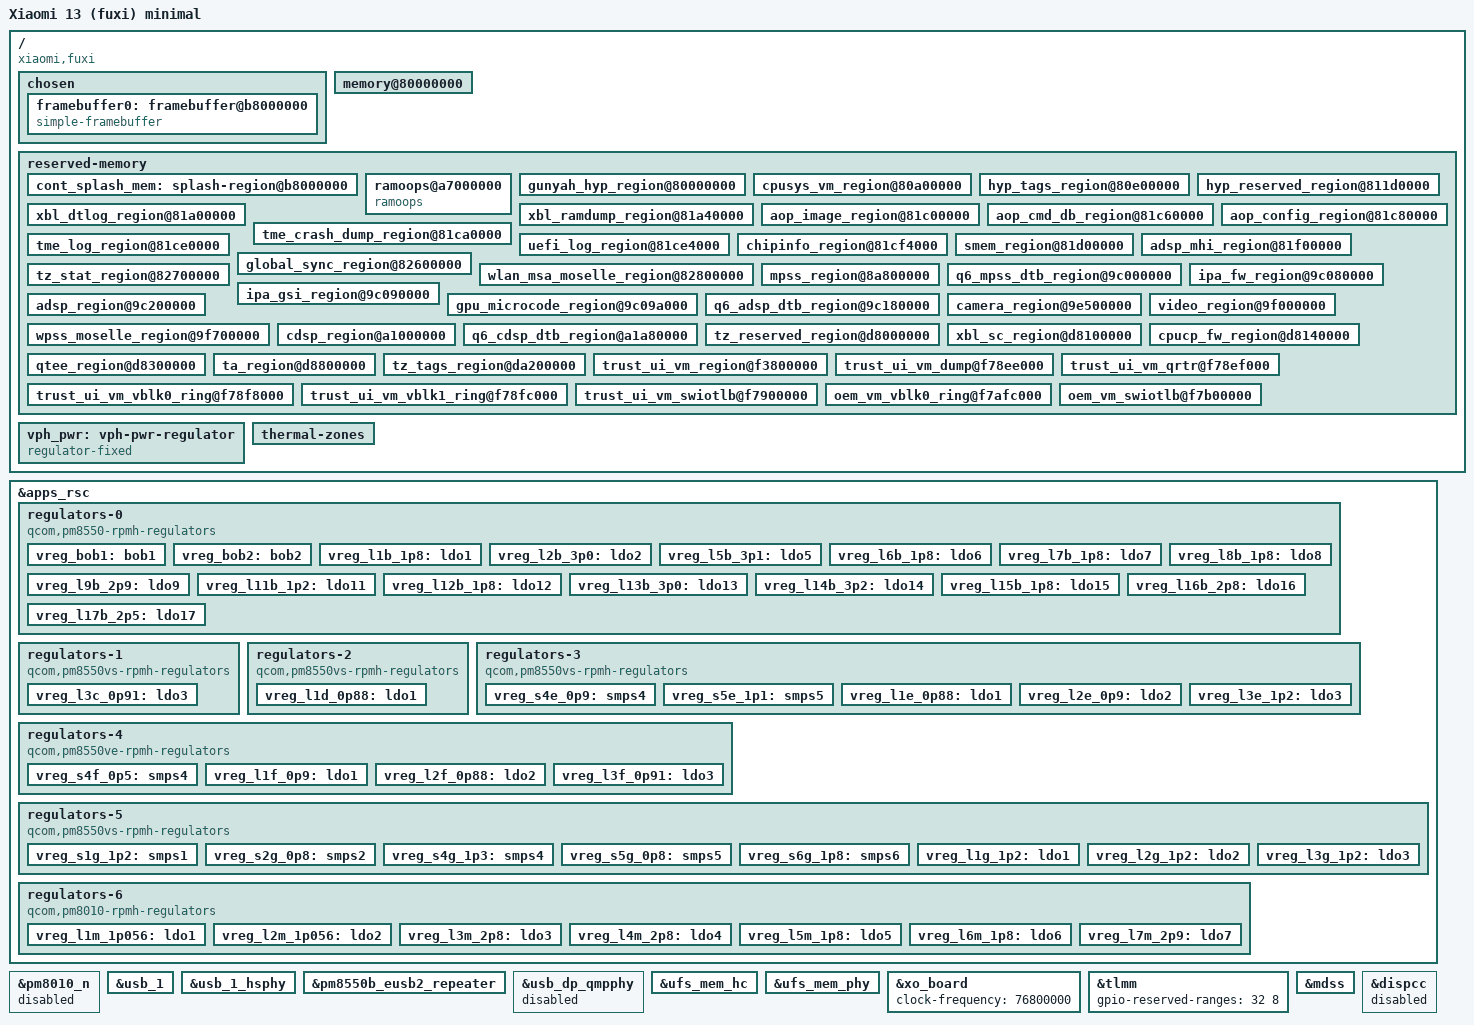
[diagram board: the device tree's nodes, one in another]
// SPDX-License-Identifier: BSD-3-Clause
/*
 * Xiaomi 13 (fuxi) 最小主线板级 DTS —— 只为“内核能启动 + USB 串口工作”
 * 生成方式：从 sm8550-mtp.dts 裁剪（保留 PMIC 调压器与 USB 子树）
 */

/dts-v1/;

#include <dt-bindings/regulator/qcom,rpmh-regulator.h>
#include "sm8550.dtsi"
#include "pm8010.dtsi"
#include "pm8550.dtsi"
#include "pm8550b.dtsi"
#define PMK8550VE_SID 5
#include "pm8550ve.dtsi"
#include "pm8550vs.dtsi"
#include "pmk8550.dtsi"
#include "pmr735d_a.dtsi"


/ {
	model = "Xiaomi 13 (fuxi) minimal";
	compatible = "xiaomi,fuxi", "qcom,sm8550";
	chassis-type = "handset";

	/* ABL 按这两项从 boot 镜像里挑 DTB（值取自厂商 fuxi DTB）；没有它们 ABL 报 Load Error */
	qcom,msm-id = <519 0x20000>, <536 0x20000>;
	qcom,board-id = <0x10008 0>;

	chosen {
		#address-cells = <2>;
		#size-cells = <2>;
		ranges;

		/*
		 * 内核 cmdline 的唯一来源（ABL 启动时内核用内建 DTB，ABL 传的 cmdline 不生效）。
		 * 末尾的空格是给旧的 UEFI 跳板（FuxiLinuxBoot 原地改写）留的余量。
		 * 不要加 console=ttyGS0：/dev/console 会变成 USB 串口，主机没打开串口时缓冲区写满，
		 * 往 /dev/console 写的进程（systemd 状态输出）全部阻塞——启动卡 6 分钟、关机永远卡住。
		 */
		bootargs = "loglevel=7 log_buf_len=2M panic=0 clk_ignore_unused pd_ignore_unused regulator_ignore_unused arm-smmu.disable_bypass=0 cpuidle.off=1 initramfs_async=0 fbcon=font:TER16x32 console=tty0 fuxi.fb=0xB8000000,1080,2400,1080,32 rdinit=/init g_cdc.idVendor=0x0525 g_cdc.idProduct=0xa4a7 g_cdc.dev_addr=02:f0:c5:13:00:02 g_cdc.host_addr=02:f0:c5:13:00:01                                                                                                                                                                                                                                                                                                                                                                                                                                                                                                                                                                                                                                                                                                                                                                                                                                ";

		/*
		 * bootloader（ABL/UEFI）留下的帧缓冲：1080x2400 XRGB8888，stride 4320。
		 * 面板是 DSI command mode，MDSS autorefresh 持续从这里取帧；simpledrm 接管它
		 * 当作标准显示设备（/dev/dri/card0 + fbcon）。内存在 reserved-memory 里保留。
		 */
		framebuffer0: framebuffer@b8000000 {
			compatible = "simple-framebuffer";
			reg = <0x0 0xb8000000 0x0 0x9e3400>;
			width = <1080>;
			height = <2400>;
			stride = <(1080 * 4)>;
			format = "x8r8g8b8";
		};
	};

	/* 内存布局取自厂商 fuxi.dtb 的 /memory 节点（去掉零长度项） */
	memory@80000000 {
		device_type = "memory";
		reg = <0x00 0x80000000 0x00 0xe00000>,
		      <0x00 0x811d0000 0x00 0x56f90000>,
		      <0x00 0xe7cb0000 0x00 0x18350000>,
		      <0x08 0x80000000 0x00 0x3b000000>,
		      <0x08 0xc0000000 0x01 0x40000000>,
		      <0x08 0xbb200000 0x00 0x1e00000>;
	};
	reserved-memory {
		#address-cells = <2>;
		#size-cells = <2>;
		ranges;

		/* 厂商 DTB 的 cont_splash_region：bootloader 帧缓冲，不能给内核当普通内存用 */
		cont_splash_mem: splash-region@b8000000 {
			reg = <0x0 0xb8000000 0x0 0x2b00000>;
			no-map;
		};

		/*
		 * 与 Android vendor DTB 完全一致的 pstore/ramoops 区域。
		 * 主线内核把 printk 写进这里；复位后 Android 的 pstore 驱动
		 * 会在 /sys/fs/pstore 下暴露 console-ramoops-0，可 adb 读取。
		 */
		ramoops@a7000000 {
			compatible = "ramoops";
			reg = <0x0 0xa7000000 0x0 0x400000>;
			console-size = <0x200000>;
			pmsg-size = <0x200000>;
		};

		gunyah_hyp_region@80000000 {
			no-map;
			reg = <0x0 0x80000000 0x0 0xa00000>;
		};
		cpusys_vm_region@80a00000 {
			no-map;
			reg = <0x0 0x80a00000 0x0 0x400000>;
		};
		hyp_tags_region@80e00000 {
			no-map;
			reg = <0x0 0x80e00000 0x0 0x3d0000>;
		};
		hyp_reserved_region@811d0000 {
			no-map;
			reg = <0x0 0x811d0000 0x0 0x30000>;
		};
		xbl_dtlog_region@81a00000 {
			no-map;
			reg = <0x0 0x81a00000 0x0 0x40000>;
		};
		xbl_ramdump_region@81a40000 {
			no-map;
			reg = <0x0 0x81a40000 0x0 0x1c0000>;
		};
		aop_image_region@81c00000 {
			no-map;
			reg = <0x0 0x81c00000 0x0 0x60000>;
		};
		aop_cmd_db_region@81c60000 {
			no-map;
			reg = <0x0 0x81c60000 0x0 0x20000>;
		};
		aop_config_region@81c80000 {
			no-map;
			reg = <0x0 0x81c80000 0x0 0x20000>;
		};
		tme_crash_dump_region@81ca0000 {
			no-map;
			reg = <0x0 0x81ca0000 0x0 0x40000>;
		};
		tme_log_region@81ce0000 {
			no-map;
			reg = <0x0 0x81ce0000 0x0 0x4000>;
		};
		uefi_log_region@81ce4000 {
			no-map;
			reg = <0x0 0x81ce4000 0x0 0x10000>;
		};
		chipinfo_region@81cf4000 {
			no-map;
			reg = <0x0 0x81cf4000 0x0 0x1000>;
		};
		smem_region@81d00000 {
			no-map;
			reg = <0x0 0x81d00000 0x0 0x200000>;
		};
		adsp_mhi_region@81f00000 {
			no-map;
			reg = <0x0 0x81f00000 0x0 0x20000>;
		};
		global_sync_region@82600000 {
			no-map;
			reg = <0x0 0x82600000 0x0 0x100000>;
		};
		tz_stat_region@82700000 {
			no-map;
			reg = <0x0 0x82700000 0x0 0x100000>;
		};
		wlan_msa_moselle_region@82800000 {
			no-map;
			reg = <0x0 0x82800000 0x0 0xc00000>;
		};
		mpss_region@8a800000 {
			no-map;
			reg = <0x0 0x8a800000 0x0 0x11800000>;
		};
		q6_mpss_dtb_region@9c000000 {
			no-map;
			reg = <0x0 0x9c000000 0x0 0x80000>;
		};
		ipa_fw_region@9c080000 {
			no-map;
			reg = <0x0 0x9c080000 0x0 0x10000>;
		};
		ipa_gsi_region@9c090000 {
			no-map;
			reg = <0x0 0x9c090000 0x0 0xa000>;
		};
		gpu_microcode_region@9c09a000 {
			no-map;
			reg = <0x0 0x9c09a000 0x0 0x2000>;
		};
		q6_adsp_dtb_region@9c180000 {
			no-map;
			reg = <0x0 0x9c180000 0x0 0x80000>;
		};
		adsp_region@9c200000 {
			no-map;
			reg = <0x0 0x9c200000 0x0 0x2300000>;
		};
		camera_region@9e500000 {
			no-map;
			reg = <0x0 0x9e500000 0x0 0x800000>;
		};
		video_region@9f000000 {
			no-map;
			reg = <0x0 0x9f000000 0x0 0x700000>;
		};
		wpss_moselle_region@9f700000 {
			no-map;
			reg = <0x0 0x9f700000 0x0 0x1900000>;
		};
		cdsp_region@a1000000 {
			no-map;
			reg = <0x0 0xa1000000 0x0 0xa80000>;
		};
		q6_cdsp_dtb_region@a1a80000 {
			no-map;
			reg = <0x0 0xa1a80000 0x0 0x80000>;
		};
		tz_reserved_region@d8000000 {
			no-map;
			reg = <0x0 0xd8000000 0x0 0x100000>;
		};
		xbl_sc_region@d8100000 {
			no-map;
			reg = <0x0 0xd8100000 0x0 0x40000>;
		};
		cpucp_fw_region@d8140000 {
			no-map;
			reg = <0x0 0xd8140000 0x0 0x1c0000>;
		};
		qtee_region@d8300000 {
			no-map;
			reg = <0x0 0xd8300000 0x0 0x500000>;
		};
		ta_region@d8800000 {
			no-map;
			reg = <0x0 0xd8800000 0x0 0x1a00000>;
		};
		tz_tags_region@da200000 {
			no-map;
			reg = <0x0 0xda200000 0x0 0x680000>;
		};
		trust_ui_vm_region@f3800000 {
			no-map;
			reg = <0x0 0xf3800000 0x0 0x40ee000>;
		};
		trust_ui_vm_dump@f78ee000 {
			no-map;
			reg = <0x0 0xf78ee000 0x0 0x1000>;
		};
		trust_ui_vm_qrtr@f78ef000 {
			no-map;
			reg = <0x0 0xf78ef000 0x0 0x9000>;
		};
		trust_ui_vm_vblk0_ring@f78f8000 {
			no-map;
			reg = <0x0 0xf78f8000 0x0 0x4000>;
		};
		trust_ui_vm_vblk1_ring@f78fc000 {
			no-map;
			reg = <0x0 0xf78fc000 0x0 0x4000>;
		};
		trust_ui_vm_swiotlb@f7900000 {
			no-map;
			reg = <0x0 0xf7900000 0x0 0x100000>;
		};
		oem_vm_vblk0_ring@f7afc000 {
			no-map;
			reg = <0x0 0xf7afc000 0x0 0x4000>;
		};
		oem_vm_swiotlb@f7b00000 {
			no-map;
			reg = <0x0 0xf7b00000 0x0 0x100000>;
		};
	};

	vph_pwr: vph-pwr-regulator {
		compatible = "regulator-fixed";
		regulator-name = "vph_pwr";
		regulator-min-microvolt = <3700000>;
		regulator-max-microvolt = <3700000>;
		regulator-always-on;
		regulator-boot-on;
	};
};

&apps_rsc {
	regulators-0 {
		compatible = "qcom,pm8550-rpmh-regulators";
		qcom,pmic-id = "b";

		vdd-bob1-supply = <&vph_pwr>;
		vdd-bob2-supply = <&vph_pwr>;
		vdd-l1-l4-l10-supply = <&vreg_s6g_1p8>;
		vdd-l2-l13-l14-supply = <&vreg_bob1>;
		vdd-l3-supply = <&vreg_s4g_1p3>;
		vdd-l5-l16-supply = <&vreg_bob1>;
		vdd-l6-l7-supply = <&vreg_bob1>;
		vdd-l8-l9-supply = <&vreg_bob1>;
		vdd-l11-supply = <&vreg_s4g_1p3>;
		vdd-l12-supply = <&vreg_s6g_1p8>;
		vdd-l15-supply = <&vreg_s6g_1p8>;
		vdd-l17-supply = <&vreg_bob2>;

		vreg_bob1: bob1 {
			regulator-name = "vreg_bob1";
			regulator-min-microvolt = <3296000>;
			regulator-max-microvolt = <3960000>;
			regulator-initial-mode = <RPMH_REGULATOR_MODE_HPM>;
		};

		vreg_bob2: bob2 {
			regulator-name = "vreg_bob2";
			regulator-min-microvolt = <2720000>;
			regulator-max-microvolt = <3960000>;
			regulator-initial-mode = <RPMH_REGULATOR_MODE_HPM>;
		};

		vreg_l1b_1p8: ldo1 {
			regulator-name = "vreg_l1b_1p8";
			regulator-min-microvolt = <1800000>;
			regulator-max-microvolt = <1800000>;
			regulator-initial-mode = <RPMH_REGULATOR_MODE_HPM>;
		};

		vreg_l2b_3p0: ldo2 {
			regulator-name = "vreg_l2b_3p0";
			regulator-min-microvolt = <3008000>;
			regulator-max-microvolt = <3008000>;
			regulator-initial-mode = <RPMH_REGULATOR_MODE_HPM>;
		};

		vreg_l5b_3p1: ldo5 {
			regulator-name = "vreg_l5b_3p1";
			regulator-min-microvolt = <3104000>;
			regulator-max-microvolt = <3104000>;
			regulator-initial-mode = <RPMH_REGULATOR_MODE_HPM>;
		};

		vreg_l6b_1p8: ldo6 {
			regulator-name = "vreg_l6b_1p8";
			regulator-min-microvolt = <1800000>;
			regulator-max-microvolt = <3008000>;
			regulator-initial-mode = <RPMH_REGULATOR_MODE_HPM>;
		};

		vreg_l7b_1p8: ldo7 {
			regulator-name = "vreg_l7b_1p8";
			regulator-min-microvolt = <1800000>;
			regulator-max-microvolt = <3008000>;
			regulator-initial-mode = <RPMH_REGULATOR_MODE_HPM>;
		};

		vreg_l8b_1p8: ldo8 {
			regulator-name = "vreg_l8b_1p8";
			regulator-min-microvolt = <1800000>;
			regulator-max-microvolt = <3008000>;
			regulator-initial-mode = <RPMH_REGULATOR_MODE_HPM>;
		};

		vreg_l9b_2p9: ldo9 {
			regulator-name = "vreg_l9b_2p9";
			regulator-min-microvolt = <2960000>;
			regulator-max-microvolt = <3008000>;
			regulator-initial-mode = <RPMH_REGULATOR_MODE_HPM>;
		};

		vreg_l11b_1p2: ldo11 {
			regulator-name = "vreg_l11b_1p2";
			regulator-min-microvolt = <1200000>;
			regulator-max-microvolt = <1504000>;
			regulator-initial-mode = <RPMH_REGULATOR_MODE_HPM>;
		};

		vreg_l12b_1p8: ldo12 {
			regulator-name = "vreg_l12b_1p8";
			regulator-min-microvolt = <1800000>;
			regulator-max-microvolt = <1800000>;
			regulator-initial-mode = <RPMH_REGULATOR_MODE_HPM>;
		};

		vreg_l13b_3p0: ldo13 {
			regulator-name = "vreg_l13b_3p0";
			regulator-min-microvolt = <3000000>;
			regulator-max-microvolt = <3000000>;
			regulator-initial-mode = <RPMH_REGULATOR_MODE_HPM>;
		};

		vreg_l14b_3p2: ldo14 {
			regulator-name = "vreg_l14b_3p2";
			regulator-min-microvolt = <3200000>;
			regulator-max-microvolt = <3200000>;
			regulator-initial-mode = <RPMH_REGULATOR_MODE_HPM>;
		};

		vreg_l15b_1p8: ldo15 {
			regulator-name = "vreg_l15b_1p8";
			regulator-min-microvolt = <1800000>;
			regulator-max-microvolt = <1800000>;
			regulator-initial-mode = <RPMH_REGULATOR_MODE_HPM>;
		};

		vreg_l16b_2p8: ldo16 {
			regulator-name = "vreg_l16b_2p8";
			regulator-min-microvolt = <2800000>;
			regulator-max-microvolt = <2800000>;
			regulator-initial-mode = <RPMH_REGULATOR_MODE_HPM>;
		};

		vreg_l17b_2p5: ldo17 {
			regulator-name = "vreg_l17b_2p5";
			regulator-min-microvolt = <2504000>;
			regulator-max-microvolt = <2504000>;
			regulator-initial-mode = <RPMH_REGULATOR_MODE_HPM>;
		};
	};

	regulators-1 {
		compatible = "qcom,pm8550vs-rpmh-regulators";
		qcom,pmic-id = "c";

		vdd-l3-supply = <&vreg_s4e_0p9>;

		vreg_l3c_0p91: ldo3 {
			regulator-name = "vreg_l3c_0p9";
			regulator-min-microvolt = <880000>;
			regulator-max-microvolt = <912000>;
			regulator-initial-mode = <RPMH_REGULATOR_MODE_HPM>;
		};
	};

	regulators-2 {
		compatible = "qcom,pm8550vs-rpmh-regulators";
		qcom,pmic-id = "d";

		vdd-l1-supply = <&vreg_s4e_0p9>;

		vreg_l1d_0p88: ldo1 {
			regulator-name = "vreg_l1d_0p88";
			regulator-min-microvolt = <880000>;
			regulator-max-microvolt = <920000>;
			regulator-initial-mode = <RPMH_REGULATOR_MODE_HPM>;
		};
	};

	regulators-3 {
		compatible = "qcom,pm8550vs-rpmh-regulators";
		qcom,pmic-id = "e";

		vdd-l1-supply = <&vreg_s4e_0p9>;
		vdd-l2-supply = <&vreg_s4e_0p9>;
		vdd-l3-supply = <&vreg_s4g_1p3>;
		vdd-s4-supply = <&vph_pwr>;
		vdd-s5-supply = <&vph_pwr>;

		vreg_s4e_0p9: smps4 {
			regulator-name = "vreg_s4e_0p9";
			regulator-min-microvolt = <904000>;
			regulator-max-microvolt = <984000>;
			regulator-initial-mode = <RPMH_REGULATOR_MODE_HPM>;
		};

		vreg_s5e_1p1: smps5 {
			regulator-name = "vreg_s5e_1p1";
			regulator-min-microvolt = <1080000>;
			regulator-max-microvolt = <1120000>;
			regulator-initial-mode = <RPMH_REGULATOR_MODE_HPM>;
		};

		vreg_l1e_0p88: ldo1 {
			regulator-name = "vreg_l1e_0p88";
			regulator-min-microvolt = <880000>;
			regulator-max-microvolt = <880000>;
			regulator-initial-mode = <RPMH_REGULATOR_MODE_HPM>;
		};

		vreg_l2e_0p9: ldo2 {
			regulator-name = "vreg_l2e_0p9";
			regulator-min-microvolt = <904000>;
			regulator-max-microvolt = <970000>;
			regulator-initial-mode = <RPMH_REGULATOR_MODE_HPM>;
		};

		vreg_l3e_1p2: ldo3 {
			regulator-name = "vreg_l3e_1p2";
			regulator-min-microvolt = <1200000>;
			regulator-max-microvolt = <1200000>;
			regulator-initial-mode = <RPMH_REGULATOR_MODE_HPM>;
		};
	};

	regulators-4 {
		compatible = "qcom,pm8550ve-rpmh-regulators";
		qcom,pmic-id = "f";

		vdd-l1-supply = <&vreg_s4e_0p9>;
		vdd-l2-supply = <&vreg_s4e_0p9>;
		vdd-l3-supply = <&vreg_s4e_0p9>;
		vdd-s4-supply = <&vph_pwr>;

		vreg_s4f_0p5: smps4 {
			regulator-name = "vreg_s4f_0p5";
			regulator-min-microvolt = <500000>;
			regulator-max-microvolt = <700000>;
			regulator-initial-mode = <RPMH_REGULATOR_MODE_HPM>;
		};

		vreg_l1f_0p9: ldo1 {
			regulator-name = "vreg_l1f_0p9";
			regulator-min-microvolt = <912000>;
			regulator-max-microvolt = <912000>;
			regulator-initial-mode = <RPMH_REGULATOR_MODE_HPM>;
		};

		vreg_l2f_0p88: ldo2 {
			regulator-name = "vreg_l2f_0p88";
			regulator-min-microvolt = <880000>;
			regulator-max-microvolt = <912000>;
			regulator-initial-mode = <RPMH_REGULATOR_MODE_HPM>;
		};

		vreg_l3f_0p91: ldo3 {
			regulator-name = "vreg_l3f_0p91";
			regulator-min-microvolt = <880000>;
			regulator-max-microvolt = <912000>;
			regulator-initial-mode = <RPMH_REGULATOR_MODE_HPM>;
		};
	};

	regulators-5 {
		compatible = "qcom,pm8550vs-rpmh-regulators";
		qcom,pmic-id = "g";

		vdd-l1-supply = <&vreg_s4g_1p3>;
		vdd-l2-supply = <&vreg_s4g_1p3>;
		vdd-l3-supply = <&vreg_s4g_1p3>;
		vdd-s1-supply = <&vph_pwr>;
		vdd-s2-supply = <&vph_pwr>;
		vdd-s3-supply = <&vph_pwr>;
		vdd-s4-supply = <&vph_pwr>;
		vdd-s5-supply = <&vph_pwr>;
		vdd-s6-supply = <&vph_pwr>;

		vreg_s1g_1p2: smps1 {
			regulator-name = "vreg_s1g_1p2";
			regulator-min-microvolt = <1200000>;
			regulator-max-microvolt = <1300000>;
			regulator-initial-mode = <RPMH_REGULATOR_MODE_HPM>;
		};

		vreg_s2g_0p8: smps2 {
			regulator-name = "vreg_s2g_0p8";
			regulator-min-microvolt = <800000>;
			regulator-max-microvolt = <1000000>;
			regulator-initial-mode = <RPMH_REGULATOR_MODE_HPM>;
		};

		/*
		 * fuxi 的 cmd-db 没有 smpg3（work/device-info/cmd-db-fuxi.txt），
		 * 保留 MTP 的 smps3 会让整块 regulators-5 以 -ENODEV 静默失败。
		 */

		vreg_s4g_1p3: smps4 {
			regulator-name = "vreg_s4g_1p3";
			regulator-min-microvolt = <1200000>;
			regulator-max-microvolt = <1352000>;
			regulator-initial-mode = <RPMH_REGULATOR_MODE_HPM>;
		};

		vreg_s5g_0p8: smps5 {
			regulator-name = "vreg_s5g_0p8";
			regulator-min-microvolt = <500000>;
			regulator-max-microvolt = <1004000>;
			regulator-initial-mode = <RPMH_REGULATOR_MODE_HPM>;
		};

		vreg_s6g_1p8: smps6 {
			regulator-name = "vreg_s6g_1p8";
			regulator-min-microvolt = <1800000>;
			regulator-max-microvolt = <2000000>;
			regulator-initial-mode = <RPMH_REGULATOR_MODE_HPM>;
		};

		vreg_l1g_1p2: ldo1 {
			regulator-name = "vreg_l1g_1p2";
			regulator-min-microvolt = <1200000>;
			regulator-max-microvolt = <1200000>;
			regulator-initial-mode = <RPMH_REGULATOR_MODE_HPM>;
		};

		vreg_l2g_1p2: ldo2 {
			regulator-name = "vreg_l2g_1p2";
			regulator-min-microvolt = <1200000>;
			regulator-max-microvolt = <1200000>;
			regulator-initial-mode = <RPMH_REGULATOR_MODE_HPM>;
		};

		vreg_l3g_1p2: ldo3 {
			regulator-name = "vreg_l3g_1p2";
			regulator-min-microvolt = <1200000>;
			regulator-max-microvolt = <1200000>;
			regulator-initial-mode = <RPMH_REGULATOR_MODE_HPM>;
		};
	};

	regulators-6 {
		compatible = "qcom,pm8010-rpmh-regulators";
		qcom,pmic-id = "m";

		vdd-l1-l2-supply = <&vreg_s4g_1p3>;
		vdd-l3-l4-supply = <&vreg_bob2>;
		vdd-l5-supply = <&vreg_s6g_1p8>;
		vdd-l6-supply = <&vreg_s6g_1p8>;
		vdd-l7-supply = <&vreg_bob1>;

		vreg_l1m_1p056: ldo1 {
			regulator-name = "vreg_l1m_1p056";
			regulator-min-microvolt = <1056000>;
			regulator-max-microvolt = <1056000>;
			regulator-initial-mode = <RPMH_REGULATOR_MODE_HPM>;
		};

		vreg_l2m_1p056: ldo2 {
			regulator-name = "vreg_l2m_1p056";
			regulator-min-microvolt = <1056000>;
			regulator-max-microvolt = <1056000>;
			regulator-initial-mode = <RPMH_REGULATOR_MODE_HPM>;
		};

		vreg_l3m_2p8: ldo3 {
			regulator-name = "vreg_l3m_2p8";
			regulator-min-microvolt = <2800000>;
			regulator-max-microvolt = <2800000>;
			regulator-initial-mode = <RPMH_REGULATOR_MODE_HPM>;
		};

		vreg_l4m_2p8: ldo4 {
			regulator-name = "vreg_l4m_2p8";
			regulator-min-microvolt = <2800000>;
			regulator-max-microvolt = <2800000>;
			regulator-initial-mode = <RPMH_REGULATOR_MODE_HPM>;
		};

		vreg_l5m_1p8: ldo5 {
			regulator-name = "vreg_l5m_1p8";
			regulator-min-microvolt = <1800000>;
			regulator-max-microvolt = <1800000>;
			regulator-initial-mode = <RPMH_REGULATOR_MODE_HPM>;
		};

		vreg_l6m_1p8: ldo6 {
			regulator-name = "vreg_l6m_1p8";
			regulator-min-microvolt = <1800000>;
			regulator-max-microvolt = <1800000>;
			regulator-initial-mode = <RPMH_REGULATOR_MODE_HPM>;
		};

		vreg_l7m_2p9: ldo7 {
			regulator-name = "vreg_l7m_2p9";
			regulator-min-microvolt = <2800000>;
			regulator-max-microvolt = <2904000>;
			regulator-initial-mode = <RPMH_REGULATOR_MODE_HPM>;
		};
	};

	/* PMIC "n"（第二颗 PM8010）在 fuxi 的 cmd-db 里没有任何资源：去掉 regulators-7 */
};

/*
 * fuxi 只有一颗 PM8010（USID 0xc）、一颗 PMR735D（0xa）：0xb/0xd 不存在（cmd-db 里也没有
 * PMIC "n" 的资源），probe 会报 spmi 通道错误并打调用栈。pmr735d_b.dtsi 不包含；pm8010.dtsi
 * 里的第二颗关掉，连同它的温度区。
 */
&pm8010_n {
	status = "disabled";
};

/ {
	thermal-zones {
		/delete-node/ pm8010-n-thermal;
	};
};

/* ===== USB：只要 gadget 串口能用（仅 USB2/eUSB2，不碰 USB3/DP combo PHY）===== */
&usb_1 {
	dr_mode = "peripheral";
	/delete-property/ usb-role-switch;
	phys = <&usb_1_hsphy>;
	phy-names = "usb2-phy";
	maximum-speed = "high-speed";
	/* 没有 SS PHY 提供 pipe clock，改用 UTMI 时钟 */
	qcom,select-utmi-as-pipe-clk;
	status = "okay";
};

&usb_1_hsphy {
	vdd-supply = <&vreg_l1e_0p88>;
	vdda12-supply = <&vreg_l3e_1p2>;

	phys = <&pm8550b_eusb2_repeater>;

	status = "okay";
};

/* repeater 在 PM8550B 上（SPMI 总线），供电同 sm8550-qrd */
&pm8550b_eusb2_repeater {
	vdd18-supply = <&vreg_l15b_1p8>;
	vdd3-supply = <&vreg_l5b_3p1>;
};

&usb_dp_qmpphy {
	vdda-phy-supply = <&vreg_l3f_0p91>;
	vdda-pll-supply = <&vreg_l3e_1p2>;

	status = "disabled";
};

/*
 * ===== UFS（M3）=====
 * 与 Android 实时 DTB（work/device-info/fuxi-live.dts，ufshc@1d84000）逐项核对过：
 * vcc=pm_humu_l17(l17b 2.504V)/1.3A、vccq=pm_v6g_l1(l1g)/1.2A、reset GPIO 210；
 * PHY vdda-phy=l1d、vdda-pll=l3e。与 sm8550-mtp 相同。
 */
&ufs_mem_hc {
	reset-gpios = <&tlmm 210 GPIO_ACTIVE_LOW>;
	vcc-supply = <&vreg_l17b_2p5>;
	vcc-max-microamp = <1300000>;
	vccq-supply = <&vreg_l1g_1p2>;
	vccq-max-microamp = <1200000>;
	vdd-hba-supply = <&vreg_l3g_1p2>;

	status = "okay";
};

&ufs_mem_phy {
	vdda-phy-supply = <&vreg_l1d_0p88>;
	vdda-pll-supply = <&vreg_l3e_1p2>;

	status = "okay";
};

&xo_board {
	clock-frequency = <76800000>;
};

/*
 * GPIO 32-39 归 TrustZone（厂商 kalama DTB: qcom,gpios-reserved = <32..39>）。
 * 缺这一行时 TLMM probe 读这些引脚的寄存器触发 XPU 违规：黑屏 + 整机卡死 + 看门狗复位。
 */
&tlmm {
	gpio-reserved-ranges = <32 8>;
};

/*
 * 显示：暂时只用 simpledrm 接管 bootloader 点亮的帧缓冲（chosen/framebuffer）。
 * MDSS 节点打开但不编 DRM_MSM：它作为"永远等不到驱动"的消费者，让 fw_devlink 把
 * mmss_noc/gem_noc 带宽和 MMCX（mdp 子节点的 power-domain）的 sync_state 一直挂起，
 * bootloader 的投票得以保留；否则这些 provider sync_state 后投票归零，画面冻结。
 * 以后接入 DRM_MSM + 面板驱动时直接接管。dispcc 保持关闭，免得它的驱动动显示时钟。
 *
 * 去掉 iommus：节点一启用，MDSS 就被挂进 SMMU 的 DMA 域（地址翻译），没人给帧缓冲建映射，
 * 显示控制器（stream 0x1c00）读 0xb8xxxxxx 全部 context fault → 黑屏。不挂 SMMU 时这个
 * stream 走 bypass，直接读物理内存。接入 DRM_MSM 时恢复。
 */
&mdss {
	/delete-property/ iommus;
	status = "okay";
};

&dispcc {
	status = "disabled";
};
